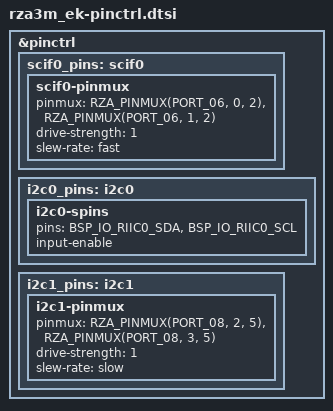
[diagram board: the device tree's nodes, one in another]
/*
 * Copyright (c) 2025 Renesas Electronics Corporation
 * SPDX-License-Identifier: Apache-2.0
 */

#include <zephyr/dt-bindings/gpio/gpio.h>
#include <zephyr/dt-bindings/pinctrl/renesas/pinctrl-rza3m.h>

&pinctrl {
	/omit-if-no-ref/ scif0_pins: scif0 {
		scif0-pinmux {
			pinmux = <RZA_PINMUX(PORT_06, 0, 2)>, /* RXD */
				 <RZA_PINMUX(PORT_06, 1, 2)>; /* TXD */
			drive-strength = <1>;
			slew-rate = "fast";
		};
	};

	/omit-if-no-ref/ i2c0_pins: i2c0 {
		i2c0-spins {
			pins = <BSP_IO_RIIC0_SDA>, <BSP_IO_RIIC0_SCL>;
			input-enable;
		};
	};

	/omit-if-no-ref/ i2c1_pins: i2c1 {
		i2c1-pinmux {
			pinmux = <RZA_PINMUX(PORT_08, 2, 5)>, /* SDA */
				 <RZA_PINMUX(PORT_08, 3, 5)>; /* SCL */
			drive-strength = <1>;
			slew-rate = "slow";
		};
	};
};
